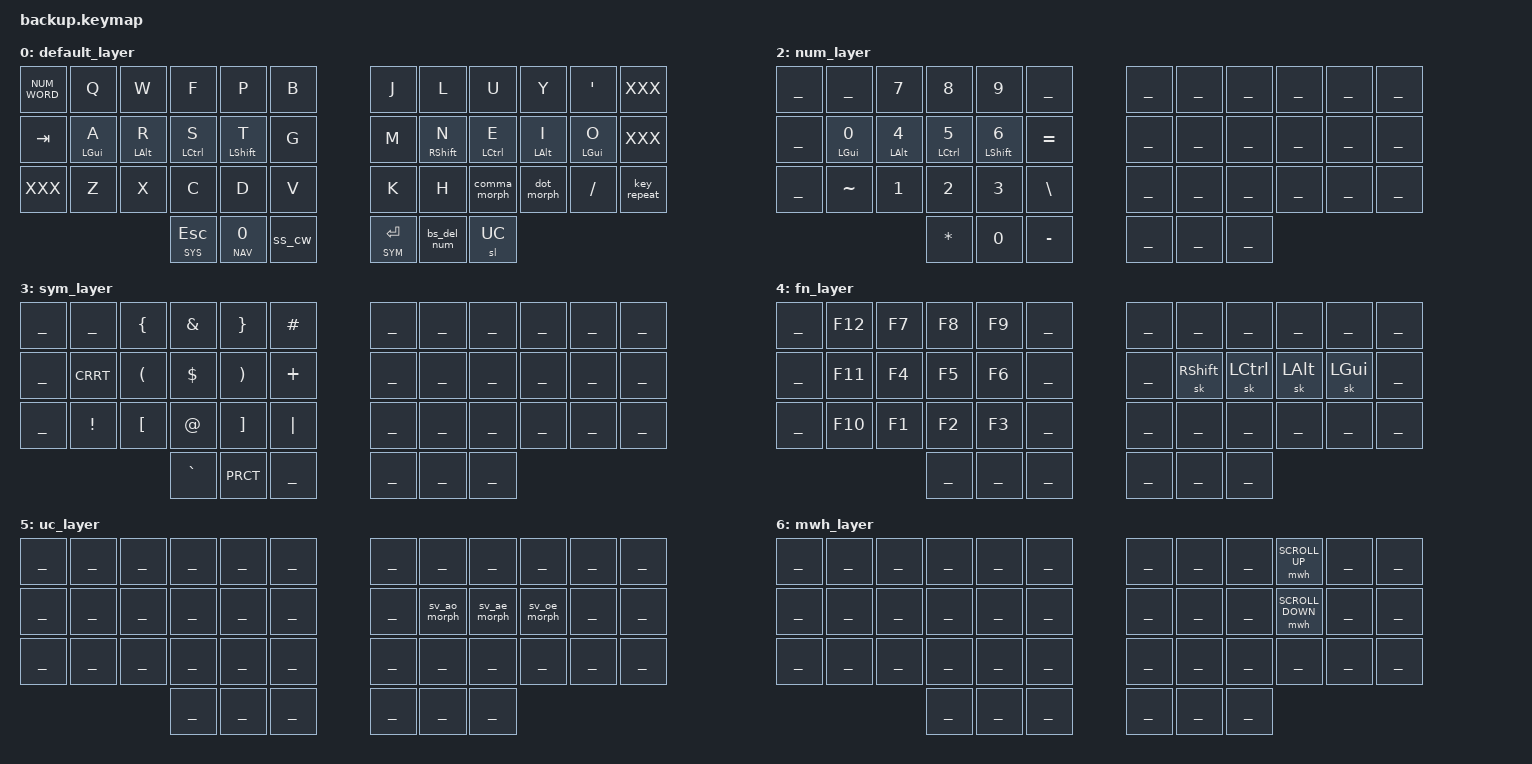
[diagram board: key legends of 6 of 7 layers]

/* Keymap */
ZMK_LAYER(default_layer,
     // ╭─────────────┬─────────────┬─────────────┬─────────────┬─────────────┬─────────────╮   ╭─────────────┬─────────────┬─────────────┬─────────────┬─────────────┬─────────────╮
           NUM_WORD        &kp Q         &kp W         &kp F         &kp P         &kp B            &kp J          &kp L         &kp U        &kp Y         &kp SQT         XXX   
     // ├─────────────├─────────────┼─────────────┼─────────────┼─────────────┼─────────────┤   ├─────────────┼─────────────┼─────────────┼─────────────┼─────────────┼─────────────┤
            &kp TAB     &hml LGUI A   &hml LALT R   &hml LCTRL S  &hml LSHFT T     &kp G            &kp M       &hmr RSHFT N  &hmr LCTRL E  &hmr LALT I   &hmr LGUI O       XXX
     // ├─────────────├─────────────┼─────────────┼─────────────┼─────────────┼─────────────┤   ├─────────────┼─────────────┼─────────────┼─────────────┼─────────────┼─────────────┤
              XXX          &kp Z         &kp X         &kp C         &kp D         &kp V            &kp K         &kp H       &comma_morph   &dot_morph    &kp SLASH    &key_repeat
     // ├─────────────├─────────────┼─────────────┼─────────────┼─────────────┼─────────────┤   ├─────────────┼─────────────┼─────────────┼─────────────┼─────────────┼─────────────┤
                                                    &lt SYS ESC  &lt_spc NAV 0     &ss_cw        &lt SYM ENTER  &bs_del_num     &sl UC  
     //                                           ╰─────────────┴─────────────┴─────────────╯   ╰─────────────┴─────────────┴─────────────╯
)

ZMK_LAYER(nav_layer,
     // ╭─────────────┬─────────────┬─────────────┬─────────────┬─────────────┬─────────────╮   ╭─────────────┬─────────────┬─────────────┬─────────────┬─────────────┬─────────────╮
              ___           ___  &kp LG(LC(LA(LEFT)))  &swap      &kp LC(TAB)  &kp LC(LS(TAB))     &kp PG_DN    &kp PG_UP     NAV_BSPC       NAV_DEL          ___           ___
     // ├─────────────├─────────────┼─────────────┼─────────────┼─────────────┼─────────────┤   ├─────────────┼─────────────┼─────────────┼─────────────┼─────────────┼─────────────┤
              ___         &sk LGUI      &sk LALT    &sk LCTRL     &sk LSHFT    &kp LC(KP_PLUS)    &kp NAV_LEFT  &kp NAV_DOWN  &kp NAV_UP   &kp NAV_RIGHT        ___           ___ 
     // ├─────────────├─────────────┼─────────────┼─────────────┼─────────────┼─────────────┤   ├─────────────┼─────────────┼─────────────┼─────────────┼─────────────┼─────────────┤
              ___           ___           ___   &kp LS(LA((PLUS))) &kp LS(LA((MINUS))) &kp LC(MINUS)  ___        &kp TAB       &copy_cut     &kp END        &kp INS         ___       
     // ├─────────────├─────────────┼─────────────┼─────────────┼─────────────┼─────────────┤   ├─────────────┼─────────────┼─────────────┼─────────────┼─────────────┼─────────────┤
                                                        ___           ___           ___               ___         CANCEL          ___
     //                                           ╰─────────────┴─────────────┴─────────────╯   ╰─────────────┴─────────────┴─────────────╯

)

ZMK_LAYER(sys_layer,
     // ╭─────────────┬─────────────┬─────────────┬─────────────┬─────────────┬─────────────╮   ╭─────────────┬─────────────┬─────────────┬─────────────┬─────────────┬─────────────╮
              ___                                  _BT_SEL_KEYS_                                     ___         &kp C_PREV   &kp C_VOL_UP   &kp C_NEXT    &win_sleep       ___
     // ├─────────────├─────────────┼─────────────┼─────────────┼─────────────┼─────────────┤   ├─────────────┼─────────────┼─────────────┼─────────────┼─────────────┼─────────────┤
            &sk LGUI      &sk LALT      &sk LCTRL     &sk LSHFT       ___           ___              ___         DSK_PREV    &kp C_VOL_DN    DSK_NEXT         ___           ___
     // ├─────────────├─────────────┼─────────────┼─────────────┼─────────────┼─────────────┤   ├─────────────┼─────────────┼─────────────┼─────────────┼─────────────┼─────────────┤
              ___                    _BT_CFG_KEYS_                    ___           ___              ___            ___           ___           ___           ___           ___
     // ├─────────────├─────────────┼─────────────┼─────────────┼─────────────┼─────────────┤   ├─────────────┼─────────────┼─────────────┼─────────────┼─────────────┼─────────────┤
                                                        ___           ___           ___              ___         &kp C_PP     &kp C_MUTE
     //                                           ╰─────────────┴─────────────┴─────────────╯   ╰─────────────┴─────────────┴─────────────╯
)

ZMK_LAYER(num_layer,
     // ╭─────────────┬─────────────┬─────────────┬─────────────┬─────────────┬─────────────╮   ╭─────────────┬─────────────┬─────────────┬─────────────┬─────────────┬─────────────╮
              ___           ___          &kp N7        &kp N8        &kp N9         ___               ___           ___           ___           ___          ___           ___
     // ├─────────────├─────────────┼─────────────┼─────────────┼─────────────┼─────────────┤   ├─────────────┼─────────────┼─────────────┼─────────────┼─────────────┼─────────────┤
              ___       &hml LGUI N0  &hml LALT N4 &hml LCTRL N5 &hml LSHFT N6   &kp EQL              ___           ___           ___           ___          ___           ___
     // ├─────────────├─────────────┼─────────────┼─────────────┼─────────────┼─────────────┤   ├─────────────┼─────────────┼─────────────┼─────────────┼─────────────┼─────────────┤
              ___         &kp TILDE       &kp N1       &kp N2        &kp N3      &kp BSLH             ___           ___           ___           ___          ___           ___
     // ├─────────────├─────────────┼─────────────┼─────────────┼─────────────┼─────────────┤   ├─────────────┼─────────────┼─────────────┼─────────────┼─────────────┼─────────────┤
                                                     &kp ASTRK       &kp N0     &kp MINUS             ___           ___           ___
     //                                           ╰─────────────┴─────────────┴─────────────╯   ╰─────────────┴─────────────┴─────────────╯
)

ZMK_LAYER(sym_layer,
     // ╭─────────────┬─────────────┬─────────────┬─────────────┬─────────────┬─────────────╮   ╭─────────────┬─────────────┬─────────────┬─────────────┬─────────────┬─────────────╮
              ___           ___         &kp LBRC      &kp AMPS     &kp RBRC      &kp HASH             ___           ___           ___           ___            ___           ___ 
     // ├─────────────├─────────────┼─────────────┼─────────────┼─────────────┼─────────────┤   ├─────────────┼─────────────┼─────────────┼─────────────┼─────────────┼─────────────┤
              ___         &kp CRRT      &kp LPAR      &kp DLLR     &kp RPAR      &kp PLUS             ___           ___           ___           ___            ___           ___
     // ├─────────────├─────────────┼─────────────┼─────────────┼─────────────┼─────────────┤   ├─────────────┼─────────────┼─────────────┼─────────────┼─────────────┼─────────────┤
              ___         &kp EXCL      &kp LBKT      &kp AT       &kp RBKT      &kp PIPE             ___           ___           ___           ___            ___           ___
     // ├─────────────├─────────────┼─────────────┼─────────────┼─────────────┼─────────────┤   ├─────────────┼─────────────┼─────────────┼─────────────┼─────────────┼─────────────┤
                                                      &kp GRAVE    &kp PRCT      &kp UNDER            ___           ___           ___
     //                                           ╰─────────────┴─────────────┴─────────────╯   ╰─────────────┴─────────────┴─────────────╯
)

ZMK_LAYER(fn_layer,
     // ╭─────────────┬─────────────┬─────────────┬─────────────┬─────────────┬─────────────╮   ╭─────────────┬─────────────┬─────────────┬─────────────┬─────────────┬─────────────╮
              ___          &kp F12       &kp F7        &kp F8        &kp F9         ___                ___           ___           ___           ___           ___           ___
     // ├─────────────├─────────────┼─────────────┼─────────────┼─────────────┼─────────────┤   ├─────────────┼─────────────┼─────────────┼─────────────┼─────────────┼─────────────┤
              ___          &kp F11       &kp F4        &kp F5        &kp F6         ___                ___       &sk RSHFT     &sk LCTRL     &sk LALT      &sk LGUI          ___
     // ├─────────────├─────────────┼─────────────┼─────────────┼─────────────┼─────────────┤   ├─────────────┼─────────────┼─────────────┼─────────────┼─────────────┼─────────────┤
              ___          &kp F10       &kp F1        &kp F2        &kp F3         ___                ___           ___           ___           ___           ___           ___
     // ├─────────────├─────────────┼─────────────┼─────────────┼─────────────┼─────────────┤   ├─────────────┼─────────────┼─────────────┼─────────────┼─────────────┼─────────────┤
                                                       ___            ___           ___                ___           ___           ___
     //                                           ╰─────────────┴─────────────┴─────────────╯   ╰─────────────┴─────────────┴─────────────╯
)

ZMK_LAYER(uc_layer,
     // ╭─────────────┬─────────────┬─────────────┬─────────────┬─────────────┬─────────────╮   ╭─────────────┬─────────────┬─────────────┬─────────────┬─────────────┬─────────────╮
              ___           ___           ___           ___           ___           ___               ___           ___           ___           ___           ___           ___
     // ├─────────────├─────────────┼─────────────┼─────────────┼─────────────┼─────────────┤   ├─────────────┼─────────────┼─────────────┼─────────────┼─────────────┼─────────────┤
              ___           ___           ___           ___           ___           ___               ___       &sv_ao_morph  &sv_ae_morph  &sv_oe_morph      ___           ___
     // ├─────────────├─────────────┼─────────────┼─────────────┼─────────────┼─────────────┤   ├─────────────┼─────────────┼─────────────┼─────────────┼─────────────┼─────────────┤
              ___           ___           ___           ___           ___           ___               ___           ___           ___           ___           ___           ___ 
     // ├─────────────├─────────────┼─────────────┼─────────────┼─────────────┼─────────────┤   ├─────────────┼─────────────┼─────────────┼─────────────┼─────────────┼─────────────┤
                                                        ___           ___           ___               ___           ___           ___
     //                                           ╰─────────────┴─────────────┴─────────────╯   ╰─────────────┴─────────────┴─────────────╯
)

ZMK_LAYER(mwh_layer,
     // ╭─────────────┬─────────────┬─────────────┬─────────────┬─────────────┬─────────────╮   ╭─────────────┬─────────────┬─────────────┬─────────────┬─────────────┬─────────────╮
              ___           ___           ___           ___           ___           ___               ___           ___           ___      &mwh SCROLL_UP     ___           ___
     // ├─────────────├─────────────┼─────────────┼─────────────┼─────────────┼─────────────┤   ├─────────────┼─────────────┼─────────────┼─────────────┼─────────────┼─────────────┤
              ___           ___           ___           ___           ___           ___               ___           ___           ___      &mwh SCROLL_DOWN   ___           ___
     // ├─────────────├─────────────┼─────────────┼─────────────┼─────────────┼─────────────┤   ├─────────────┼─────────────┼─────────────┼─────────────┼─────────────┼─────────────┤
              ___           ___            ___          ___           ___           ___               ___           ___           ___           ___           ___           ___
     // ├─────────────├─────────────┼─────────────┼─────────────┼─────────────┼─────────────┤   ├─────────────┼─────────────┼─────────────┼─────────────┼─────────────┼─────────────┤
                                                        ___           ___           ___               ___           ___           ___
     //                                           ╰─────────────┴─────────────┴─────────────╯   ╰─────────────┴─────────────┴─────────────╯
)


